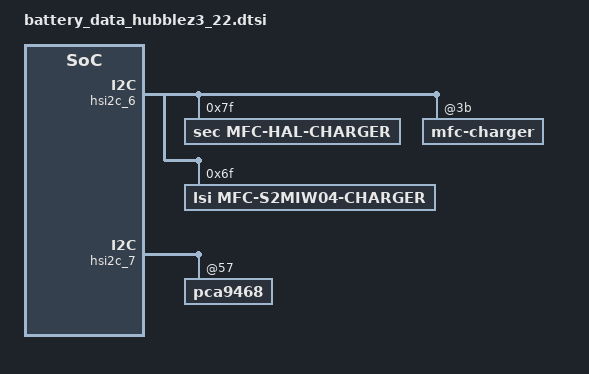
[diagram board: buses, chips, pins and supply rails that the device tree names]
/* SAMSUNG UNIVERSAL9830 board device tree source
 *
 * Copyright (c) 2018 Samsung Electronics Co., Ltd.
 *		http://www.samsung.com
 *
 * This program is free software; you can redistribute it and/or modify
 * it under the terms of the GNU General Public License version 2 as
 * published by the Free Software Foundation.
 */

#include "battery_data_hubble_common.dtsi"

/ {
	fragment@battery {
		target-path = "/";
		__overlay__ {
			battery {
				battery,temp_table_adc = <293 334 392 458 535 625 738 860 998 1164 1345 1546
					1764 2002 2238 2479 2707 2931 3135 3306 3443 3556 3644>;
				battery,temp_table_data = <900 850 800 750 700 650 600 550 500 450 400 350
					300 250 200 150 100 50 0 (-50) (-100) (-150) (-200)>;

				battery,usb_temp_table_adc = <275 322 380 450 530 624 734 861 1005 1171 1354 1555
					1775 2004 2240 2468 2695 2914 3103 3270 3398 3514 3610>;
				battery,usb_temp_table_data = <900 850 800 750 700 650 600 550 500 450 400 350
					300 250 200 150 100 50 0 (-50) (-100) (-150) (-200)>;

				battery,chg_temp_table_adc = <255 295 356 424 502 593 703 828 970 1135 1322 1525
					1748 1987 2230 2474 2706 2923 3123 3307 3452 3577 3679>;
				battery,chg_temp_table_data = <900 850 800 750 700 650 600 550 500 450 400 350
					300 250 200 150 100 50 0 (-50) (-100) (-150) (-200)>;

				battery,wpc_temp_table_adc = <293 334 392 458 535 625 738 860 998 1164 1345 1546
					1764 2002 2238 2479 2707 2931 3135 3306 3443 3556 3644>;
				battery,wpc_temp_table_data = <900 850 800 750 700 650 600 550 500 450 400 350
					300 250 200 150 100 50 0 (-50) (-100) (-150) (-200)>;

				battery,dchg_temp_table_adc = <103224 119646 145452 175950 211140 251022 297942 356592 419934 492660 574770 663918
					764796 870366 978282 1083852 1189422 1287954 1379448 1459212 1527246 1583550 1630470>;
				battery,dchg_temp_table_data = <900 850 800 750 700 650 600 550 500 450 400 350
					300 250 200 150 100 50 0 (-50) (-100) (-150) (-200)>;

				battery,swelling_low_temp_current = <1150>;	/* 0.24C */
				battery,swelling_low_temp_current_2nd = <450>;	/* 0.1C */
				battery,swelling_low_temp_current_3rd = <3450>;	/* 0.72C */
				battery,swelling_low_temp_topoff = <242>;	/* 0.05C */
				battery,swelling_high_temp_current = <1700>;	/* 0.36C */
				battery,swelling_high_temp_topoff = <242>;	/* 0.05C */
				battery,swelling_wc_high_temp_current = <1150>;	/* 0.24C */
				battery,swelling_wc_low_temp_current = <1150>;	/* 0.24C */
 				battery,swelling_wc_low_temp_current_2nd = <450>;	/* 0.1C */
				battery,swelling_wc_low_temp_current_3rd = <3450>;	/* 0.72C */

				battery,ttf_hv_charge_current = <2750>;
				battery,ttf_hv_wireless_charge_current = <1430>;
				battery,ttf_wireless_charge_current = <910>;
				battery,ttf_dc25_charge_current = <4750>;
				battery,ttf_dc45_charge_current = <5800>;
				battery,max_charging_charge_power = <45000>; /* 45W */
				battery,battery_full_capacity = <5000>;

				battery,chg_high_temp = <550>;
				battery,chg_high_temp_recovery = <530>;

				battery,dchg_high_temp = <550>;
				battery,dchg_high_temp_recovery = <420>;
				battery,dchg_high_batt_temp = <400>;
				battery,dchg_high_batt_temp_recovery = <390>;

				battery,wpc_high_temp = <370>;
				battery,wpc_high_temp_recovery = <350>;
				battery,wpc_lcd_on_high_temp = <370>;
				battery,wpc_lcd_on_high_temp_rec = <350>;

				battery,dc_step_chg_cond_vol = <4130 4290 4380>; /*<45w 3step> STEP_CHARGING_CONDITION_VOLTAGE */ 
				battery,dc_step_chg_cond_iin = <3160 2255 0>; /* <45w 3step> STEP_CHARGING_CONDITION_INPUT_CURRENT */
				battery,dc_step_chg_val_vfloat = <4130 4290 4380>; /* <45w 3step> STEP_CHARGING_CONDITION_FLOAT_VOLTAGE */
				battery,dc_step_chg_val_iout = <8000 6320 4510>; /* <45w 3step> */
				battery,dc_step_chg_cond_soc = <20 60 100 20 60 100 20 60 100 20 60 100 20 60 100>; /* <45w 3step> STEP_CHARGING_CONDITION_SOC */

				battery,snkcap_data = /bits/ 8 <0x04 0x2C 0x91 0x01 0x36 0xC8 0xD0 0x02 0x00 0xC8 0x90
								0x41 0x8B 0x51 0x21 0xDC 0xC0>;
			};

			max77705-fuelgauge {
				fuelgauge,fg_resistor = <5>;
				fuelgauge,qrtable20 = <0x1000>;
				fuelgauge,qrtable30 = <0x0B00>;
				fuelgauge,capacity = <0x0708>;
				/* fullcapnom(=capacity), dPacc, dQacc,  rcomp0, tempco */
				fuelgauge,fg_reset_wa_data = <0x0708 0x3200 0x01C2 0x002C 0x242D>;
				fuelgauge,ttf_capacity = <4150>;
				fuelgauge,cv_data = <
					4511	801	1503
					4480	803	1493
					4414	806	1483
					4358	809	1472
					4290	812	1462
					4249	814	1452
					4187	817	1442
					4141	820	1431
					4087	822	1421
					4056	825	1411
					3982	827	1401
					3931	830	1390
					3896	832	1380
					3846	835	1370
					3803	837	1360
					3733	840	1349
					3690	842	1339
					3616	847	1319
					3575	849	1308
					3490	851	1298
					3452	853	1288
					3377	858	1268
					3342	860	1257
					3275	862	1247
					3228	864	1237
					3133	866	1227
					3067	872	1196
					3019	874	1186
					2929	879	1155
					2896	881	1145
					2843	883	1134
					2792	885	1124
					2754	887	1114
					2695	892	1083
					2660	893	1073
					2625	895	1063
					2580	897	1052
					2531	898	1042
					2492	902	1022
					2450	903	1012
					2410	905	1001
					2348	908	981
					2296	909	971
					2263	910	960
					2214	915	930
					2182	916	919
					2147	919	899
					2103	920	889
					2051	922	878
					2019	924	858
					1981	927	837
					1948	928	827
					1911	930	807
					1879	932	796
					1834	933	786
					1795	935	766
					1761	938	735
					1722	942	704
					1689	944	684
					1649	946	663
					1592	948	643
					1532	950	622
					1493	954	581
					1462	955	571
					1410	958	530
					1362	959	520
					1338	960	510
					1291	964	459
					1264	968	418
					1237	968	407
					1213	969	397
					1169	974	336
					1127	975	325
					1105	975	315
					1073	980	244
					1049	982	213
					1010	983	192
					993		984	182
					972		986	151
					955		988	110
					932		990	90
					881		990	80
					864		996	59
					761		1000	10
					710		1000	0
				>;
			};

			cable-info {
				full_check_current_1st = <727>;
				full_check_current_2nd = <242>;
			};

			wireless-power-info {
				current_group_0 {
					ttf_charge_current = <910>;
				};
				current_group_1 {
					ttf_charge_current = <1430>;
				};
				current_group_2 {
					ttf_charge_current = <2150>;
				};
				current_group_3 {
					ttf_charge_current = <2625>;
				};
			};
		};
	};
};

&pinctrl_0 {
	wchg-pdrc {
		samsung,pin-function = <0xf>;
		samsung,pin-pud = <0>;
	};
};

#define FOD_FLAG_NONE			0
#define FOD_FLAG_ADD			1
#define FOD_FLAG_USE_CC			2
#define FOD_FLAG_USE_DEFAULT	3
#define SET_FOD_CC(_flag)		(FOD_FLAG_ ##_flag)
#define SET_FOD_CV(_flag)		(FOD_FLAG_ ##_flag << 4)
#define SET_FOD_FULL(_flag)		(FOD_FLAG_ ##_flag << 8)

&hsi2c_6 {
	mfc-hal-charger@7f {
		compatible = "sec,mfc-hal-charger";
		reg = <0x7f>;
		status = "okay";

		battery,wpc_det = <&gpa2 0 0>;

		battery,charger_name = "max77705-charger";
	};

	mfc-charger@3b {
		fod_list {
			count = <2>;

			pad_0x00 { /* DEFAULT */
				flag = <(SET_FOD_CC(ADD) | SET_FOD_CV(ADD) | SET_FOD_FULL(ADD))>;
				cc = <150 58 142 48 150 31 150 26 155 7 156 6>;
				cv = <150 88 142 78 150 61 150 56 155 37 156 36>;
				full = <255 127 255 127 255 127 255 127 255 127 255 127>;
			};

			pad_0x31 { /* DREAM PAD(V) */
				flag = <(SET_FOD_CC(ADD) | SET_FOD_CV(USE_DEFAULT) | SET_FOD_FULL(USE_DEFAULT))>;
				cc = <150 8 142 (-2) 150 (-19) 150 (-24) 155 (-43) 156 (-44)>;
			};
		};
	};

	mfc-s2miw04-charger@6f {
		compatible = "lsi,mfc-s2miw04-charger";
		reg = <0x6f>;
		status = "okay";

		pinctrl-names = "default";
		pinctrl-0 = <&pdet_b &wpc_det &ping_nen &wchg_pdrc &wpc_en &wpc_int>;

		battery,wpc_int = <&gpa3 1 0>;
		battery,wpc_det = <&gpa2 0 0>;
		battery,pdet_b = <&gpa2 6 0>;
		battery,mst_pwr_en = <&gpm18 0 0>;
		battery,ping_nen = <&gpa2 1 0>;
		battery,wpc_pdrc = <&gpa4 1 0>;
		battery,wpc_en = <&gpm10 0 0>;

		battery,charger_name = "max77705-charger";
		battery,fuelgauge_name = "max77705-fuelgauge";
		battery,wireless_charger_name = "mfc-charger";
		battery,wc_cover_rpp = <0x44>;
		battery,phone_fod_threshold = <0x3b>;
		battery,oc_fod1 = <1100>;
		battery,wireless20_vout_list = <9 9 9>; /* WIRELESS_VOUT_11V, 11V, 11V */
		battery,wireless20_vrect_list = <10 11 11>; /* MFC_AFC_CONF_12V_TX, 12.5V, 12.5V */
		battery,wireless20_max_power_list = <2 3 3>; /* SEC_WIRELESS_RX_POWER_12W, 15W, 15W */

		fod_list {
			count = <3>;

			pad_0x00 { /* DEFAULT */
				flag = <(SET_FOD_CC(ADD) | SET_FOD_CV(USE_CC) | SET_FOD_FULL(ADD))>;
				cc = <0x06 0xAA 0x06 0xAA 0x06 0xAA 0x06 0x99 0x06 0x99 0x06 0x99 0x0C 0x85 0x0C 0x85 0x08 0x9E 0x08 0x9E>;
				full = <0xFF 0xFF 0xFF 0xFF 0xFF 0xFF 0xFF 0xFF 0xFF 0xFF 0xFF 0xFF 0xFF 0xFF 0xFF 0xFF 0xFF 0xFF 0xFF 0xFF>;
			};

			pad_0x31 { /* DREAM PAD - STAND */
				flag = <(SET_FOD_CC(ADD) | SET_FOD_CV(USE_CC) | SET_FOD_FULL(USE_DEFAULT))>;
				cc = <0x06 0xAA 0x06 0xAA 0x06 0xAA 0x06 0x99 0x06 0x99 0x06 0x99 0x0C 0x71 0x0C 0x71 0x08 0x9E 0x08 0x9E>;
			};

			pad_0xA1 { /* DAVINCHI PAD(V) */
				flag = <(SET_FOD_CC(ADD) | SET_FOD_CV(USE_CC) | SET_FOD_FULL(USE_DEFAULT))>;
				cc = <0x06 0xAA 0x06 0xAA 0x06 0xAA 0x06 0x99 0x06 0x99 0x06 0x99 0x0C 0x85 0x0C 0x85 0x08 0x9E 0x08 0xE1>;
			};
		};
	};
};

&hsi2c_7 {
	pca9468@57 {
		pca9468,input-itopoff = <400000>; /* 400mA */
	};
};
